# f29h85x_esm_safetyagg_regs register map
Vendor: Texas Instruments
Peripheral module from a debugger description file (folder C29).
Registers are 32-bit, read-write, no defined reset value unless marked. A register's access mark holds for its fields unless they carry their own. Offsets are as the file gives them; lines under a group give offsets from that group; [hi:lo] are bit positions; {n}, {i} and the like mark numbered series; 'fields as' and 'values as' point back to an identical list; <NAME> marks a mode.

## ESM_SAFETYAGG_REGS — ESM SAFETYAGG Registers
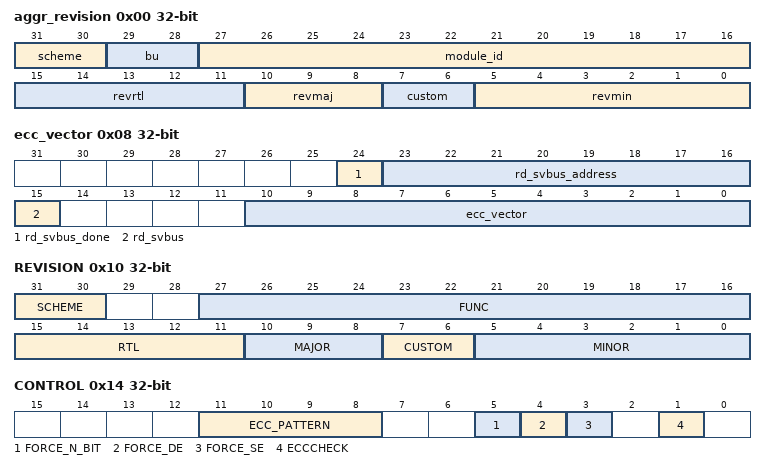
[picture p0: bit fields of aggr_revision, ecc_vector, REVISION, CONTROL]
0x00 aggr_revision ro — Aggregator Revision Register
  [31:30] scheme, [29:28] bu, [27:16] module_id, [15:11] revrtl, [10:8] revmaj, [7:6] custom, [5:0] revmin
0x08 ecc_vector
  [24] rd_svbus_done, [23:16] rd_svbus_address, [15] rd_svbus, [10:0] ecc_vector
0x0C misc_status ro
  [10:0] num_rams
0x10 EdcRegs group
  0x10 REVISION ro
    [31:30] SCHEME — Reserved
    [27:16] FUNC — Assigned func id
    [15:11] RTL — RTL version of the module
    [10:8] MAJOR — Major revision of module
    [7:6] CUSTOM — Special version
    [5:0] MINOR — Minor revision of module
  0x14 CONTROL
    [11:8] ECC_PATTERN — Data Pattern
    [5] FORCE_N_BIT — Incremental Injection
    [4] FORCE_DE — Inject Double bit error
    [3] FORCE_SE — Inject Single bit error
    [1] ECCCHECK — Enable ECC Checkers
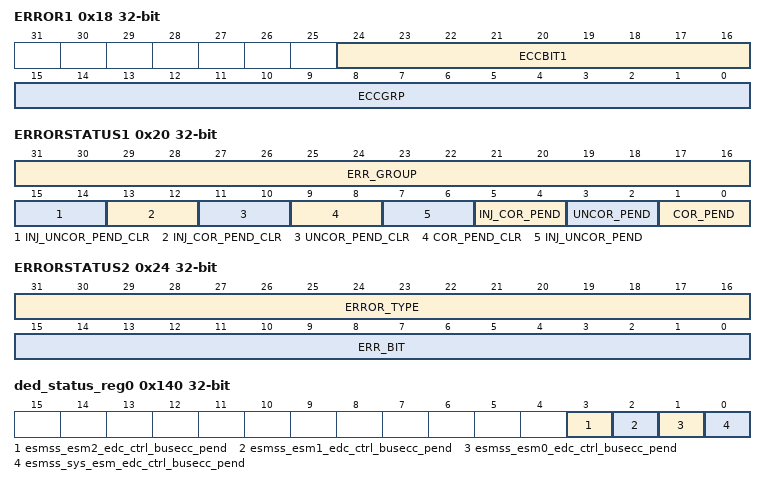
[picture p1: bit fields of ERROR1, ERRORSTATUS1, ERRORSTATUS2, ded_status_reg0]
  0x18 ERROR1
    [24:16] ECCBIT1
    [15:0] ECCGRP — Group of Checker to inject
  0x1C ERROR2
    [8:0] ECCBIT2
  0x20 ERRORSTATUS1 access per field
    [31:16] ERR_GROUP ro — Specify Checker that reported Error
    [15:14] INJ_UNCOR_PEND_CLR rw — Injected uncorrectable pending interrupts
    [13:12] INJ_COR_PEND_CLR rw — Injected correctable pending interrupts
    [11:10] UNCOR_PEND_CLR rw — Uncorrectable pending interrupts
    [9:8] COR_PEND_CLR rw — Correctable pending interrupts
    [7:6] INJ_UNCOR_PEND rw — Injected uncorrectable pending interrupts
    [5:4] INJ_COR_PEND rw — Injected correctable pending interrupts
    [3:2] UNCOR_PEND rw — Uncorrectable Pending
    [1:0] COR_PEND rw — Correctable Pending
  0x24 ERRORSTATUS2 ro
    [31:16] ERROR_TYPE
    [15:0] ERR_BIT — error bit
0x13C ded_eoi_reg — EOI Register
  [0] eoi_wr
0x140 ded_status_reg0 — Interrupt Status Register 0
  [3] esmss_esm2_edc_ctrl_busecc_pend, [2] esmss_esm1_edc_ctrl_busecc_pend, [1] esmss_esm0_edc_ctrl_busecc_pend, [0] esmss_sys_esm_edc_ctrl_busecc_pend
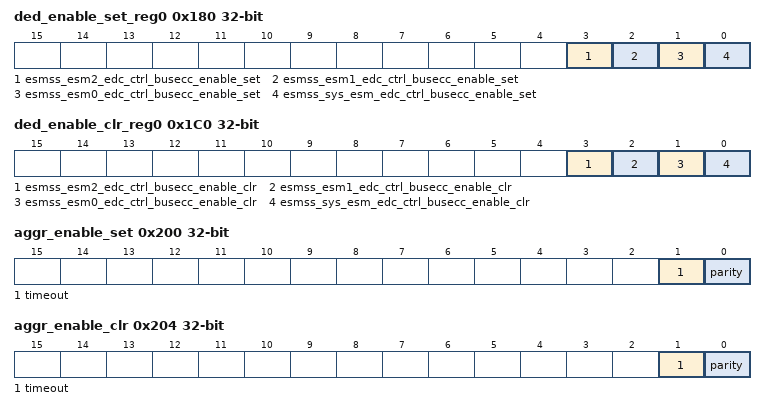
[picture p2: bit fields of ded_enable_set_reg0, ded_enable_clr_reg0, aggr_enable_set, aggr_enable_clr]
0x180 ded_enable_set_reg0 — Interrupt Enable Set Register 0
  [3] esmss_esm2_edc_ctrl_busecc_enable_set, [2] esmss_esm1_edc_ctrl_busecc_enable_set, [1] esmss_esm0_edc_ctrl_busecc_enable_set, [0] esmss_sys_esm_edc_ctrl_busecc_enable_set
0x1C0 ded_enable_clr_reg0 — Interrupt Enable Clear Register 0
  [3] esmss_esm2_edc_ctrl_busecc_enable_clr, [2] esmss_esm1_edc_ctrl_busecc_enable_clr, [1] esmss_esm0_edc_ctrl_busecc_enable_clr, [0] esmss_sys_esm_edc_ctrl_busecc_enable_clr
0x200 aggr_enable_set — AGGR interrupt enable set Register
  [1] timeout, [0] parity
0x204 aggr_enable_clr — AGGR interrupt enable clear Register
  [1] timeout, [0] parity
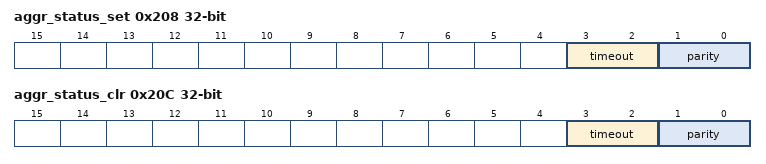
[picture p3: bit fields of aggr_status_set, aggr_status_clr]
0x208 aggr_status_set — AGGR interrupt status set Register
  [3:2] timeout, [1:0] parity
0x20C aggr_status_clr — AGGR interrupt status clear Register
  [3:2] timeout, [1:0] parity
